# RT584ZCM33 register map
Series: ARMv8-M Mainline; File version: 1.0
CPU: CM33 r0p0, little endian, MPU, no FPU, VTOR, 3 interrupt priority bits
Registers are 32-bit, read-write, reset 0x0 unless marked. A register's access mark holds for its fields unless they carry their own. Offsets are from the block's base; [hi:lo] are bit positions; {n}, {i} and the like mark numbered series.

## GPIO_Non-Secure — GPIO Non-Secure Register block
Base 0x40001000
Same registers: GPIO_Secure 0x50001000
0x00 SET_STATE_REG — Write 1 to set the corresponding output signal.
0x04 CLR_STATE_REG — Write 1 to clear the corresponding output signal.
0x08 SET_OUT_REG — Write 1 to set the corresponding GPIO as an output.
0x0C SET_IN_REG — Write 1 to set the corresponding GPIO as an input.
0x10 INTR_EN_REG — Write 1 to enable the corresponding interrupt.
0x14 INTR_DIS_REG wo — Write 1 to disable the corresponding interrupt.
0x18 INTR_EDGE_REG — Write 1 to set the corresponding interrupt as the edge trigger.
0x1C INTR_LEVEL_REG — Write 1 to set the corresponding interrupt as the level trigger.
0x20 INTR_HIGH_REG — Write 1 to set interrupts to active high or rising edge.
0x24 INTR_LOW_REG wo — Write 1 to set interrupts to active low or falling edge.
0x28 SET_INTR_ANYEDGE_REG — Write 1 to override interrupt edge selection & instead interrupt on ANY edge.
0x2C CLR_INTR_ANYEDGE_REG wo — Write 1 to clear the any edge setting of the corresponding interrupt.
0x30 CLR_INTR_STATUS_REG wo — Write 1 to clear the corresponding interrupt status.
0x38 SET_INPUT_EN_REG — Write 1 to set the corresponding input enable.
0x3C DIS_INPUT_EN_REG wo — Each bit that is set to 1 allows/enables the corresponding input signal. Read for current state of all active low output enable signals. All inputs default to enabled.
0x40 DEB_EN_REG — Write 1 to enable the corresponding input debounce.
0x44 DEB_DIS_REG wo — Write 1 to disable the corresponding input debounce.
0x48 DEB_SEL_REG — deb sel
  [2:0] debounce_sel — De-bounce time selection 0 : 32 slow clocks 1 : 64 slow clocks 2 : 128 slow clocks 3 : 256 slow clocks 4 : 512 slow clocks 5 : 1024 slow clocks 6 : 2048 slow clocks 7 : 4096 slow clocks
    0=B_0_to_2_ITEM0 (32 slow clocks); 1=B_0_to_2_ITEM1 (64 slow clocks); 2=B_0_to_2_ITEM2 (128 slow clocks); 3=B_0_to_2_ITEM3 (256 slow clocks); 4=B_0_to_2_ITEM4 (512 slow clocks); 5=B_0_to_2_ITEM5 (1024 slow clocks); 6=B_0_to_2_ITEM6 (2048 slow clocks); 7=B_0_to_2_ITEM7 (4096 slow clocks)
0x50 SET_DS_EN_REG — Write 1 to set the corresponding GPIO for enabling Deepsleep wakeup. Once enabling Deepsleep wakeup, System will wakeup in Deepsleep when the corresponding GPIO is low. If the GPIO high wakeup is preferred, write 1 to the corresponding bit of set_ds_inv_en.
0x54 DIS_DS_EN_REG wo — Write 1 to disable deepsleep wakeup for the corresponding GPIO.
0x58 SET_DS_INV_REG — Write 1 to set the corresponding GPIO wakeup polarity of high in Deepsleep.
0x5C DIS_DS_INV_REG wo — Write 1 to set the corresponding GPIO wakeup polarity of low in Deepsleep.

## DPD_Non-Secure — DPD Non-Secure Register block
Base 0x40005000
Same registers: DPD_Secure 0x50005000
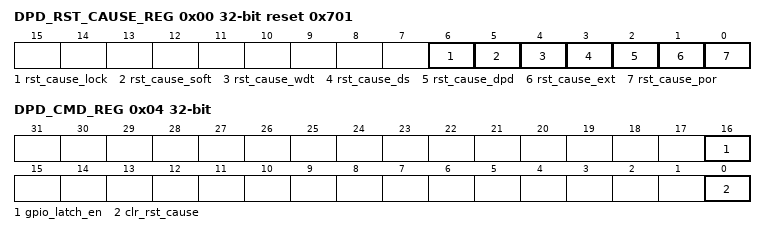
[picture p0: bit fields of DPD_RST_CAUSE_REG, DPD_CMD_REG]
0x00 DPD_RST_CAUSE_REG ro reset 0x701 — dpd rst cause
  [6] rst_cause_lock — High indicates the reset cause is mcu lockup. Cleared by clr_rst_cause.
    0=B_6 (High indicates the reset cause is mcu lockup. Cleared by clr_rst_cause.)
  [5] rst_cause_soft — High indicates the reset cause is soft reset. Cleared by clr_rst_cause.
    0=B_5 (High indicates the reset cause is soft reset. Cleared by clr_rst_cause.)
  [4] rst_cause_wdt — High indicates the reset cause is watchdog timer. Cleared by clr_rst_cause.
    0=B_4 (High indicates the reset cause is watchdog timer. Cleared by clr_rst_cause.)
  [3] rst_cause_ds — High indicates the reset cause is deep sleep wakeup. Cleared by clr_rst_cause.
    0=B_3 (High indicates the reset cause is deep sleep wakeup. Cleared by clr_rst_cause.)
  [2] rst_cause_dpd — High indicates the reset cause is deep powerdown wakeup. Cleared by clr_rst_cause.
    0=B_2 (High indicates the reset cause is deep powerdown wakeup. Cleared by clr_rst_cause.)
  [1] rst_cause_ext — High indicates the reset cause is external reset. Cleared by clr_rst_cause.
    0=B_1 (High indicates the reset cause is external reset. Cleared by clr_rst_cause.)
  [0] rst_cause_por — High indicates the reset cause is POR. Cleared by clr_rst_cause.
    0=B_0 (High indicates the reset cause is POR. Cleared by clr_rst_cause.)
0x04 DPD_CMD_REG — dpd cmd
  [16] gpio_latch_en — WARNING!!! This is a test function only and don't enable in normal operation. GPIO latch enable. When 1 is set, the GPIO settings, like output enable, output state, pull state, driving state, etc, will be latched and kept. This function is used manually kept the GPIO states in Deep powerdown mode.
    0=B_16 (WARNING!!! This is a test function only and don't enable in normal operation. GPIO latch enable. When 1 is set, the GPIO settings, like output enable, output state, pull state, driving state, etc, will be latched and kept. This function is used manually kept the GPIO states in Deep powerdown mode.)
  [0] clr_rst_cause wo — Write 1 to clear all reset cause to 0
    0=B_0 (Write 1 to clear all reset cause to 0)
0x08 DPD_GPIO_EN_REG — Set which GPIO can wake up in Deep Power Down mode. 0: Disable the corresponding GPIO 1: Enable the corresponding GPIO
0x0C DPD_GPIO_INV_REG — Set the wake up polarity of the corresponding GPIO. 0: level low 1: level high
{0x10+4i} DPD_RET{i}_REG (i=0..3) — Retention Register {i}
